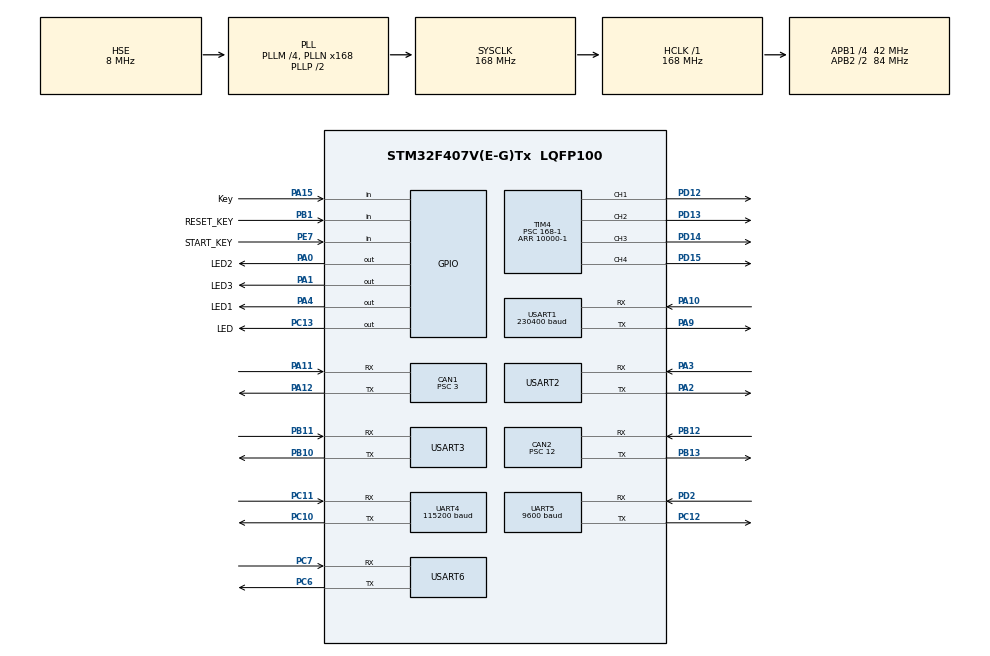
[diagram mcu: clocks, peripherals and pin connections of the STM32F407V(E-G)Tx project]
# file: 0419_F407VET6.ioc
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CAN1.BS1=CAN_BS1_10TQ
CAN1.BS2=CAN_BS2_3TQ
CAN1.CalculateBaudRate=1000000
CAN1.CalculateTimeBit=1000
CAN1.CalculateTimeQuantum=71.42857142857143
CAN1.Prescaler=3
CAN2.ABOM=ENABLE
CAN2.BS1=CAN_BS1_3TQ
CAN2.BS2=CAN_BS2_3TQ
CAN2.CalculateBaudRate=500000
CAN2.CalculateTimeBit=2000
CAN2.CalculateTimeQuantum=285.7142857142857
CAN2.Prescaler=12
Dma.Request0=USART3_TX
Dma.Request1=USART3_RX
Dma.Request2=USART2_TX
Dma.Request3=USART2_RX
Dma.Request4=UART4_TX
Dma.Request5=UART4_RX
Dma.Request6=UART5_TX
Dma.Request7=UART5_RX
Dma.Request8=USART1_TX
Dma.Request9=USART1_RX
Dma.UART4_RX.5.Direction=DMA_PERIPH_TO_MEMORY
Dma.UART4_RX.5.FIFOMode=DMA_FIFOMODE_DISABLE
Dma.UART4_RX.5.Instance=DMA1_Stream2
Dma.UART4_RX.5.MemDataAlignment=DMA_MDATAALIGN_BYTE
Dma.UART4_RX.5.MemInc=DMA_MINC_ENABLE
Dma.UART4_RX.5.Mode=DMA_CIRCULAR
Dma.UART4_RX.5.PeriphDataAlignment=DMA_PDATAALIGN_BYTE
Dma.UART4_RX.5.PeriphInc=DMA_PINC_DISABLE
Dma.UART4_RX.5.Priority=DMA_PRIORITY_LOW
Dma.UART4_TX.4.Direction=DMA_MEMORY_TO_PERIPH
Dma.UART4_TX.4.FIFOMode=DMA_FIFOMODE_DISABLE
Dma.UART4_TX.4.Instance=DMA1_Stream4
Dma.UART4_TX.4.MemDataAlignment=DMA_MDATAALIGN_BYTE
Dma.UART4_TX.4.MemInc=DMA_MINC_ENABLE
Dma.UART4_TX.4.Mode=DMA_NORMAL
Dma.UART4_TX.4.PeriphDataAlignment=DMA_PDATAALIGN_BYTE
Dma.UART4_TX.4.PeriphInc=DMA_PINC_DISABLE
Dma.UART4_TX.4.Priority=DMA_PRIORITY_LOW
Dma.UART5_RX.7.Direction=DMA_PERIPH_TO_MEMORY
Dma.UART5_RX.7.FIFOMode=DMA_FIFOMODE_DISABLE
Dma.UART5_RX.7.Instance=DMA1_Stream0
Dma.UART5_RX.7.MemDataAlignment=DMA_MDATAALIGN_BYTE
Dma.UART5_RX.7.MemInc=DMA_MINC_ENABLE
Dma.UART5_RX.7.Mode=DMA_CIRCULAR
Dma.UART5_RX.7.PeriphDataAlignment=DMA_PDATAALIGN_BYTE
Dma.UART5_RX.7.PeriphInc=DMA_PINC_DISABLE
Dma.UART5_RX.7.Priority=DMA_PRIORITY_LOW
Dma.UART5_TX.6.Direction=DMA_MEMORY_TO_PERIPH
Dma.UART5_TX.6.FIFOMode=DMA_FIFOMODE_DISABLE
Dma.UART5_TX.6.Instance=DMA1_Stream7
Dma.UART5_TX.6.MemDataAlignment=DMA_MDATAALIGN_BYTE
Dma.UART5_TX.6.MemInc=DMA_MINC_ENABLE
Dma.UART5_TX.6.Mode=DMA_NORMAL
Dma.UART5_TX.6.PeriphDataAlignment=DMA_PDATAALIGN_BYTE
Dma.UART5_TX.6.PeriphInc=DMA_PINC_DISABLE
Dma.UART5_TX.6.Priority=DMA_PRIORITY_LOW
Dma.USART1_RX.9.Direction=DMA_PERIPH_TO_MEMORY
Dma.USART1_RX.9.FIFOMode=DMA_FIFOMODE_DISABLE
Dma.USART1_RX.9.Instance=DMA2_Stream2
Dma.USART1_RX.9.MemDataAlignment=DMA_MDATAALIGN_BYTE
Dma.USART1_RX.9.MemInc=DMA_MINC_ENABLE
Dma.USART1_RX.9.Mode=DMA_CIRCULAR
Dma.USART1_RX.9.PeriphDataAlignment=DMA_PDATAALIGN_BYTE
Dma.USART1_RX.9.PeriphInc=DMA_PINC_DISABLE
Dma.USART1_RX.9.Priority=DMA_PRIORITY_LOW
Dma.USART1_TX.8.Direction=DMA_MEMORY_TO_PERIPH
Dma.USART1_TX.8.FIFOMode=DMA_FIFOMODE_DISABLE
Dma.USART1_TX.8.Instance=DMA2_Stream7
Dma.USART1_TX.8.MemDataAlignment=DMA_MDATAALIGN_BYTE
Dma.USART1_TX.8.MemInc=DMA_MINC_ENABLE
Dma.USART1_TX.8.Mode=DMA_NORMAL
Dma.USART1_TX.8.PeriphDataAlignment=DMA_PDATAALIGN_BYTE
Dma.USART1_TX.8.PeriphInc=DMA_PINC_DISABLE
Dma.USART1_TX.8.Priority=DMA_PRIORITY_LOW
Dma.USART2_RX.3.Direction=DMA_PERIPH_TO_MEMORY
Dma.USART2_RX.3.FIFOMode=DMA_FIFOMODE_DISABLE
Dma.USART2_RX.3.Instance=DMA1_Stream5
Dma.USART2_RX.3.MemDataAlignment=DMA_MDATAALIGN_BYTE
Dma.USART2_RX.3.MemInc=DMA_MINC_ENABLE
Dma.USART2_RX.3.Mode=DMA_CIRCULAR
Dma.USART2_RX.3.PeriphDataAlignment=DMA_PDATAALIGN_BYTE
Dma.USART2_RX.3.PeriphInc=DMA_PINC_DISABLE
Dma.USART2_RX.3.Priority=DMA_PRIORITY_LOW
Dma.USART2_TX.2.Direction=DMA_MEMORY_TO_PERIPH
Dma.USART2_TX.2.FIFOMode=DMA_FIFOMODE_DISABLE
Dma.USART2_TX.2.Instance=DMA1_Stream6
Dma.USART2_TX.2.MemDataAlignment=DMA_MDATAALIGN_BYTE
Dma.USART2_TX.2.MemInc=DMA_MINC_ENABLE
Dma.USART2_TX.2.Mode=DMA_NORMAL
Dma.USART2_TX.2.PeriphDataAlignment=DMA_PDATAALIGN_BYTE
Dma.USART2_TX.2.PeriphInc=DMA_PINC_DISABLE
Dma.USART2_TX.2.Priority=DMA_PRIORITY_LOW
Dma.USART3_RX.1.Direction=DMA_PERIPH_TO_MEMORY
Dma.USART3_RX.1.FIFOMode=DMA_FIFOMODE_DISABLE
Dma.USART3_RX.1.Instance=DMA1_Stream1
Dma.USART3_RX.1.MemDataAlignment=DMA_MDATAALIGN_BYTE
Dma.USART3_RX.1.MemInc=DMA_MINC_ENABLE
Dma.USART3_RX.1.Mode=DMA_CIRCULAR
Dma.USART3_RX.1.PeriphDataAlignment=DMA_PDATAALIGN_BYTE
Dma.USART3_RX.1.PeriphInc=DMA_PINC_DISABLE
Dma.USART3_RX.1.Priority=DMA_PRIORITY_LOW
Dma.USART3_TX.0.Direction=DMA_MEMORY_TO_PERIPH
Dma.USART3_TX.0.FIFOMode=DMA_FIFOMODE_DISABLE
Dma.USART3_TX.0.Instance=DMA1_Stream3
Dma.USART3_TX.0.MemDataAlignment=DMA_MDATAALIGN_BYTE
Dma.USART3_TX.0.MemInc=DMA_MINC_ENABLE
Dma.USART3_TX.0.Mode=DMA_NORMAL
Dma.USART3_TX.0.PeriphDataAlignment=DMA_PDATAALIGN_BYTE
Dma.USART3_TX.0.PeriphInc=DMA_PINC_DISABLE
Dma.USART3_TX.0.Priority=DMA_PRIORITY_LOW
FREERTOS.BinarySemaphores01=SemMove,Dynamic,NULL,Depleted
FREERTOS.Events01=EventGroups_Car,Dynamic,NULL
FREERTOS.INCLUDE_pcTaskGetTaskName=1
FREERTOS.INCLUDE_vTaskCleanUpResources=1
FREERTOS.INCLUDE_xSemaphoreGetMutexHolder=1
FREERTOS.INCLUDE_xTaskAbortDelay=1
FREERTOS.INCLUDE_xTaskGetHandle=1
FREERTOS.Mutexes01=Mutex_Print,Dynamic,NULL,Depleted
FREERTOS.Queues01=Queue_Status,1,uint8_t,0,Dynamic,NULL,NULL
FREERTOS.Tasks01=Task_Main,24,512,AppTask_Main,As weak,NULL,Dynamic,NULL,NULL;Task_MaixCAM,25,512,AppTask_MaixCAM,As weak,NULL,Dynamic,NULL,NULL;Task_BlueTooth,26,512,AppTask_BlueTooth,As weak,NULL,Dynamic,NULL,NULL;Task_HWT101,27,512,AppTask_HWT101,As weak,NULL,Dynamic,NULL,NULL;Task_Show,23,512,AppTask_Show,As weak,NULL,Dynamic,NULL,NULL;Task_ChassisControl,32,512,AppTask_ChassisControl,As weak,NULL,Dynamic,NULL,NULL;Task_Key,8,128,AppTask_Key,As weak,NULL,Dynamic,NULL,NULL
FREERTOS.configCHECK_FOR_STACK_OVERFLOW=2
FREERTOS.configENABLE_FPU=1
FREERTOS.configGENERATE_RUN_TIME_STATS=1
FREERTOS.configMAX_TASK_NAME_LEN=32
FREERTOS.configMINIMAL_STACK_SIZE=128
FREERTOS.configRECORD_STACK_HIGH_ADDRESS=1
FREERTOS.configTOTAL_HEAP_SIZE=30000
FREERTOS.configUSE_DAEMON_TASK_STARTUP_HOOK=0
FREERTOS.configUSE_STATS_FORMATTING_FUNCTIONS=1
Mcu.Family=STM32F4
Mcu.Name=STM32F407V(E-G)Tx
Mcu.Package=LQFP100
NVIC.CAN1_RX0_IRQn=true\:5\:0\:false\:false\:true\:false\:true\:true\:true
NVIC.CAN2_RX0_IRQn=true\:5\:0\:false\:false\:true\:true\:true\:true\:true
NVIC.DMA1_Stream0_IRQn=true\:0\:0\:true\:false\:true\:false\:false\:true\:true
NVIC.DMA1_Stream1_IRQn=true\:0\:0\:true\:false\:true\:false\:false\:true\:true
NVIC.DMA1_Stream2_IRQn=true\:0\:0\:true\:false\:true\:false\:false\:true\:true
NVIC.DMA1_Stream3_IRQn=true\:0\:0\:true\:false\:true\:false\:false\:true\:true
NVIC.DMA1_Stream4_IRQn=true\:0\:0\:true\:false\:true\:false\:false\:true\:true
NVIC.DMA1_Stream5_IRQn=true\:5\:0\:false\:false\:true\:false\:false\:true\:true
NVIC.DMA1_Stream6_IRQn=true\:5\:0\:false\:false\:true\:false\:false\:true\:true
NVIC.DMA1_Stream7_IRQn=true\:5\:0\:false\:false\:true\:false\:false\:true\:true
NVIC.DMA2_Stream2_IRQn=true\:5\:0\:false\:false\:true\:false\:false\:true\:true
NVIC.DMA2_Stream7_IRQn=true\:5\:0\:false\:false\:true\:false\:false\:true\:true
NVIC.PriorityGroup=NVIC_PRIORITYGROUP_4
NVIC.TIM7_IRQn=true\:15\:0\:false\:false\:true\:false\:false\:true\:true
NVIC.TimeBase=TIM7_IRQn
NVIC.TimeBaseIP=TIM7
NVIC.UART4_IRQn=true\:0\:0\:true\:false\:true\:false\:true\:true\:true
NVIC.UART5_IRQn=true\:0\:0\:true\:false\:true\:false\:true\:true\:true
NVIC.USART1_IRQn=true\:5\:0\:false\:false\:true\:false\:true\:true\:true
NVIC.USART2_IRQn=true\:0\:0\:true\:false\:true\:false\:false\:true\:true
NVIC.USART3_IRQn=true\:0\:0\:true\:false\:true\:false\:false\:true\:true
NVIC.USART6_IRQn=true\:5\:0\:false\:false\:true\:false\:true\:true\:true
PA0-WKUP.GPIO_Label=LED2
PA0-WKUP.Signal=GPIO_Output
PA1.GPIO_Label=LED3
PA1.Signal=GPIO_Output
PA10.Mode=Asynchronous
PA10.Signal=USART1_RX
PA11.Mode=CAN_Activate
PA11.Signal=CAN1_RX
PA12.Mode=CAN_Activate
PA12.Signal=CAN1_TX
PA13.Mode=Serial_Wire
PA13.Signal=SYS_JTMS-SWDIO
PA14.Mode=Serial_Wire
PA14.Signal=SYS_JTCK-SWCLK
PA15.GPIO_Label=Key
PA15.GPIO_PuPd=GPIO_PULLUP
PA15.Signal=GPIO_Input
PA2.Mode=Asynchronous
PA2.Signal=USART2_TX
PA3.Mode=Asynchronous
PA3.Signal=USART2_RX
PA4.GPIO_Label=LED1
PA4.Signal=GPIO_Output
PA9.Mode=Asynchronous
PA9.Signal=USART1_TX
PB1.GPIO_Label=RESET_KEY
PB1.GPIO_PuPd=GPIO_PULLUP
PB1.Signal=GPIO_Input
PB10.Mode=Asynchronous
PB10.Signal=USART3_TX
PB11.Mode=Asynchronous
PB11.Signal=USART3_RX
PB12.Mode=CAN_Activate
PB12.Signal=CAN2_RX
PB13.Mode=CAN_Activate
PB13.Signal=CAN2_TX
PC10.Mode=Asynchronous
PC10.Signal=UART4_TX
PC11.Mode=Asynchronous
PC11.Signal=UART4_RX
PC12.Mode=Asynchronous
PC12.Signal=UART5_TX
PC13-ANTI_TAMP.GPIO_Label=LED
PC13-ANTI_TAMP.PinState=GPIO_PIN_SET
PC13-ANTI_TAMP.Signal=GPIO_Output
PC6.Mode=Asynchronous
PC6.Signal=USART6_TX
PC7.Mode=Asynchronous
PC7.Signal=USART6_RX
PD12.Signal=S_TIM4_CH1
PD13.Signal=S_TIM4_CH2
PD14.Signal=S_TIM4_CH3
PD15.Signal=S_TIM4_CH4
PD2.Mode=Asynchronous
PD2.Signal=UART5_RX
PE7.GPIO_Label=START_KEY
PE7.GPIO_PuPd=GPIO_PULLUP
PE7.Signal=GPIO_Input
PH0-OSC_IN.Mode=HSE-External-Oscillator
PH0-OSC_IN.Signal=RCC_OSC_IN
PH1-OSC_OUT.Mode=HSE-External-Oscillator
PH1-OSC_OUT.Signal=RCC_OSC_OUT
ProjectManager.HeapSize=0x200
ProjectManager.StackSize=0x400
ProjectManager.TargetToolchain=MDK-ARM V5.32
RCC.48MHZClocksFreq_Value=84000000
RCC.AHBFreq_Value=168000000
RCC.APB1CLKDivider=RCC_HCLK_DIV4
RCC.APB1Freq_Value=42000000
RCC.APB1TimFreq_Value=84000000
RCC.APB2CLKDivider=RCC_HCLK_DIV2
RCC.APB2Freq_Value=84000000
RCC.APB2TimFreq_Value=168000000
RCC.CortexFreq_Value=168000000
RCC.HCLKFreq_Value=168000000
RCC.HSE_VALUE=8000000
RCC.HSI_VALUE=16000000
RCC.LSE_VALUE=32768
RCC.LockedElements=AHBOutput
RCC.PLLM=4
RCC.PLLN=168
RCC.PLLSourceVirtual=RCC_PLLSOURCE_HSE
RCC.SYSCLKFreq_VALUE=168000000
RCC.SYSCLKSource=RCC_SYSCLKSOURCE_PLLCLK
RCC.VCOOutputFreq_Value=336000000
SH.S_TIM4_CH1.0=TIM4_CH1,PWM Generation1 CH1
SH.S_TIM4_CH2.0=TIM4_CH2,PWM Generation2 CH2
SH.S_TIM4_CH3.0=TIM4_CH3,PWM Generation3 CH3
SH.S_TIM4_CH4.0=TIM4_CH4,PWM Generation4 CH4
TIM4.Channel-PWM\ Generation1\ CH1=TIM_CHANNEL_1
TIM4.Channel-PWM\ Generation2\ CH2=TIM_CHANNEL_2
TIM4.Channel-PWM\ Generation3\ CH3=TIM_CHANNEL_3
TIM4.Channel-PWM\ Generation4\ CH4=TIM_CHANNEL_4
TIM4.Period=10000-1
TIM4.Prescaler=168-1
UART4.BaudRate=115200
UART4.VirtualMode=Asynchronous
UART5.BaudRate=9600
UART5.VirtualMode=Asynchronous
USART1.BaudRate=230400
USART1.VirtualMode=VM_ASYNC
USART2.VirtualMode=VM_ASYNC
USART3.VirtualMode=VM_ASYNC
USART6.VirtualMode=VM_ASYNC
VP_FREERTOS_VS_CMSIS_V2.Mode=CMSIS_V2
VP_SYS_VS_tim7.Mode=TIM7
VP_TIM4_VS_ClockSourceINT.Mode=Internal
board=custom

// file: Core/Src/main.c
/* USER CODE BEGIN Header */
/**
  ******************************************************************************
  * @file           : main.c
  * @brief          : Main program body
  ******************************************************************************
  * @attention
  *
  * Copyright (c) 2025 STMicroelectronics.
  * All rights reserved.
  *
  * This software is licensed under terms that can be found in the LICENSE file
  * in the root directory of this software component.
  * If no LICENSE file comes with this software, it is provided AS-IS.
  *
  ******************************************************************************
  */
/* USER CODE END Header */
#include "main.h"
#include "cmsis_os.h"
#include "can.h"
#include "dma.h"
#include "tim.h"
#include "usart.h"
#include "gpio.h"

void SystemClock_Config(void);
void MX_FREERTOS_Init(void);

int main(void)
{

  /* MCU Configuration--------------------------------------------------------*/

  /* Reset of all peripherals, Initializes the Flash interface and the Systick. */
  HAL_Init();

  /* Configure the system clock */
  SystemClock_Config();

  /* Initialize all configured peripherals */
  MX_GPIO_Init();
  MX_DMA_Init();
  MX_USART1_UART_Init();
  MX_USART2_UART_Init();
  MX_USART3_UART_Init();
  MX_CAN1_Init();
  MX_CAN2_Init();
  MX_UART4_Init();
  MX_UART5_Init();
  MX_USART6_UART_Init();
  MX_TIM4_Init();
  /* USER CODE BEGIN 2 */
  bsp_Init();
  uint8_t show_init[] = "";
  uint8_t show_start[] = "++++++";
                SCREEN_Dispaly(show_init);       //��Ļ��ʾ
  app_Init();
  AppObjCreate();

  printf("Hello\r\n");
                SCREEN_Dispaly(show_start);       //��Ļ��ʾ

  /* USER CODE END 2 */

  /* Init scheduler */
  osKernelInitialize();

  /* Call init function for freertos objects (in cmsis_os2.c) */
  MX_FREERTOS_Init();

  /* Start scheduler */
  osKernelStart();

  /* We should never get here as control is now taken by the scheduler */

  /* Infinite loop */
  while (1)
  {

  }
}

void SystemClock_Config(void)
{
  RCC_OscInitTypeDef RCC_OscInitStruct = {0};
  RCC_ClkInitTypeDef RCC_ClkInitStruct = {0};

  /** Configure the main internal regulator output voltage
  */
  __HAL_RCC_PWR_CLK_ENABLE();
  __HAL_PWR_VOLTAGESCALING_CONFIG(PWR_REGULATOR_VOLTAGE_SCALE1);

  /** Initializes the RCC Oscillators according to the specified parameters
  * in the RCC_OscInitTypeDef structure.
  */
  RCC_OscInitStruct.OscillatorType = RCC_OSCILLATORTYPE_HSE;
  RCC_OscInitStruct.HSEState = RCC_HSE_ON;
  RCC_OscInitStruct.PLL.PLLState = RCC_PLL_ON;
  RCC_OscInitStruct.PLL.PLLSource = RCC_PLLSOURCE_HSE;
  RCC_OscInitStruct.PLL.PLLM = 4;
  RCC_OscInitStruct.PLL.PLLN = 168;
  RCC_OscInitStruct.PLL.PLLP = RCC_PLLP_DIV2;
  RCC_OscInitStruct.PLL.PLLQ = 4;
  if (HAL_RCC_OscConfig(&RCC_OscInitStruct) != HAL_OK)
  {
    Error_Handler();
  }

  /** Initializes the CPU, AHB and APB buses clocks
  */
  RCC_ClkInitStruct.ClockType = RCC_CLOCKTYPE_HCLK|RCC_CLOCKTYPE_SYSCLK
                              |RCC_CLOCKTYPE_PCLK1|RCC_CLOCKTYPE_PCLK2;
  RCC_ClkInitStruct.SYSCLKSource = RCC_SYSCLKSOURCE_PLLCLK;
  RCC_ClkInitStruct.AHBCLKDivider = RCC_SYSCLK_DIV1;
  RCC_ClkInitStruct.APB1CLKDivider = RCC_HCLK_DIV4;
  RCC_ClkInitStruct.APB2CLKDivider = RCC_HCLK_DIV2;

  if (HAL_RCC_ClockConfig(&RCC_ClkInitStruct, FLASH_LATENCY_5) != HAL_OK)
  {
    Error_Handler();
  }
}

void HAL_TIM_PeriodElapsedCallback(TIM_HandleTypeDef *htim)
{
  if (htim->Instance == TIM7) {
    HAL_IncTick();
  }
}

void Error_Handler(void)
{
  __disable_irq();
  while (1)
  {
  }
}

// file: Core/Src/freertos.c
/* USER CODE BEGIN Header */
/**
  ******************************************************************************
  * File Name          : freertos.c
  * Description        : Code for freertos applications
  ******************************************************************************
  * @attention
  *
  * Copyright (c) 2025 STMicroelectronics.
  * All rights reserved.
  *
  * This software is licensed under terms that can be found in the LICENSE file
  * in the root directory of this software component.
  * If no LICENSE file comes with this software, it is provided AS-IS.
  *
  ******************************************************************************
  */
/* USER CODE END Header */

#include "FreeRTOS.h"
#include "task.h"
#include "main.h"
#include "cmsis_os.h"

/* Definitions for Task_Main */
osThreadId_t Task_MainHandle;
const osThreadAttr_t Task_Main_attributes = {
  .name = "Task_Main",
  .stack_size = 512 * 4,
  .priority = (osPriority_t) osPriorityNormal,
};
/* Definitions for Task_MaixCAM */
osThreadId_t Task_MaixCAMHandle;
const osThreadAttr_t Task_MaixCAM_attributes = {
  .name = "Task_MaixCAM",
  .stack_size = 512 * 4,
  .priority = (osPriority_t) osPriorityNormal1,
};
/* Definitions for Task_BlueTooth */
osThreadId_t Task_BlueToothHandle;
const osThreadAttr_t Task_BlueTooth_attributes = {
  .name = "Task_BlueTooth",
  .stack_size = 512 * 4,
  .priority = (osPriority_t) osPriorityNormal2,
};
/* Definitions for Task_HWT101 */
osThreadId_t Task_HWT101Handle;
const osThreadAttr_t Task_HWT101_attributes = {
  .name = "Task_HWT101",
  .stack_size = 512 * 4,
  .priority = (osPriority_t) osPriorityNormal3,
};
/* Definitions for Task_Show */
osThreadId_t Task_ShowHandle;
const osThreadAttr_t Task_Show_attributes = {
  .name = "Task_Show",
  .stack_size = 512 * 4,
  .priority = (osPriority_t) osPriorityBelowNormal7,
};
/* Definitions for Task_ChassisControl */
osThreadId_t Task_ChassisControlHandle;
const osThreadAttr_t Task_ChassisControl_attributes = {
  .name = "Task_ChassisControl",
  .stack_size = 512 * 4,
  .priority = (osPriority_t) osPriorityAboveNormal,
};
/* Definitions for Task_Key */
osThreadId_t Task_KeyHandle;
const osThreadAttr_t Task_Key_attributes = {
  .name = "Task_Key",
  .stack_size = 128 * 4,
  .priority = (osPriority_t) osPriorityLow,
};
/* Definitions for Queue_Status */
osMessageQueueId_t Queue_StatusHandle;
const osMessageQueueAttr_t Queue_Status_attributes = {
  .name = "Queue_Status"
};
/* Definitions for Mutex_Print */
osMutexId_t Mutex_PrintHandle;
const osMutexAttr_t Mutex_Print_attributes = {
  .name = "Mutex_Print"
};
/* Definitions for SemMove */
osSemaphoreId_t SemMoveHandle;
const osSemaphoreAttr_t SemMove_attributes = {
  .name = "SemMove"
};
/* Definitions for EventGroups_Car */
osEventFlagsId_t EventGroups_CarHandle;
const osEventFlagsAttr_t EventGroups_Car_attributes = {
  .name = "EventGroups_Car"
};

void AppTask_Main(void *argument);
void AppTask_MaixCAM(void *argument);
void AppTask_BlueTooth(void *argument);
void AppTask_HWT101(void *argument);
void AppTask_Show(void *argument);
void AppTask_ChassisControl(void *argument);
void AppTask_Key(void *argument);

void MX_FREERTOS_Init(void); /* (MISRA C 2004 rule 8.1) */

/* Hook prototypes */
void configureTimerForRunTimeStats(void);
unsigned long getRunTimeCounterValue(void);
void vApplicationStackOverflowHook(xTaskHandle xTask, signed char *pcTaskName);

/* USER CODE BEGIN 1 */
/* Functions needed when configGENERATE_RUN_TIME_STATS is on */
__weak void configureTimerForRunTimeStats(void)
{

}

unsigned long getRunTimeCounterValue(void) {
    return get_system_ms();
}
/* USER CODE END 1 */

/* USER CODE BEGIN 4 */
void vApplicationStackOverflowHook(xTaskHandle xTask, signed char *pcTaskName)
{
   /* Run time stack overflow checking is performed if
   configCHECK_FOR_STACK_OVERFLOW is defined to 1 or 2. This hook function is
   called if a stack overflow is detected. */
}
/* USER CODE END 4 */

void MX_FREERTOS_Init(void) {
  /* Create the mutex(es) */
  /* creation of Mutex_Print */
  Mutex_PrintHandle = osMutexNew(&Mutex_Print_attributes);

  /* Create the semaphores(s) */
  /* creation of SemMove */
  SemMoveHandle = osSemaphoreNew(1, 0, &SemMove_attributes);

  /* Create the queue(s) */
  /* creation of Queue_Status */
  Queue_StatusHandle = osMessageQueueNew (1, sizeof(uint8_t), &Queue_Status_attributes);

  /* Create the thread(s) */
  /* creation of Task_Main */
  Task_MainHandle = osThreadNew(AppTask_Main, NULL, &Task_Main_attributes);

  /* creation of Task_MaixCAM */
  Task_MaixCAMHandle = osThreadNew(AppTask_MaixCAM, NULL, &Task_MaixCAM_attributes);

  /* creation of Task_BlueTooth */
  Task_BlueToothHandle = osThreadNew(AppTask_BlueTooth, NULL, &Task_BlueTooth_attributes);

  /* creation of Task_HWT101 */
  Task_HWT101Handle = osThreadNew(AppTask_HWT101, NULL, &Task_HWT101_attributes);

  /* creation of Task_Show */
  Task_ShowHandle = osThreadNew(AppTask_Show, NULL, &Task_Show_attributes);

  /* creation of Task_ChassisControl */
  Task_ChassisControlHandle = osThreadNew(AppTask_ChassisControl, NULL, &Task_ChassisControl_attributes);

  /* creation of Task_Key */
  Task_KeyHandle = osThreadNew(AppTask_Key, NULL, &Task_Key_attributes);

  /* creation of EventGroups_Car */
  EventGroups_CarHandle = osEventFlagsNew(&EventGroups_Car_attributes);

}

__weak void AppTask_Main(void *argument)
{
  for(;;)
  {
    osDelay(1);
  }
}

__weak void AppTask_MaixCAM(void *argument)
{
  for(;;)
  {
    osDelay(1);
  }
}

__weak void AppTask_BlueTooth(void *argument)
{
  for(;;)
  {
    osDelay(1);
  }
}

__weak void AppTask_HWT101(void *argument)
{
  for(;;)
  {
    osDelay(1);
  }
}

__weak void AppTask_Show(void *argument)
{
  for(;;)
  {
    osDelay(1);
  }
}

__weak void AppTask_ChassisControl(void *argument)
{
  for(;;)
  {
    osDelay(1);
  }
}

__weak void AppTask_Key(void *argument)
{
  for(;;)
  {
    osDelay(1);
  }
}
